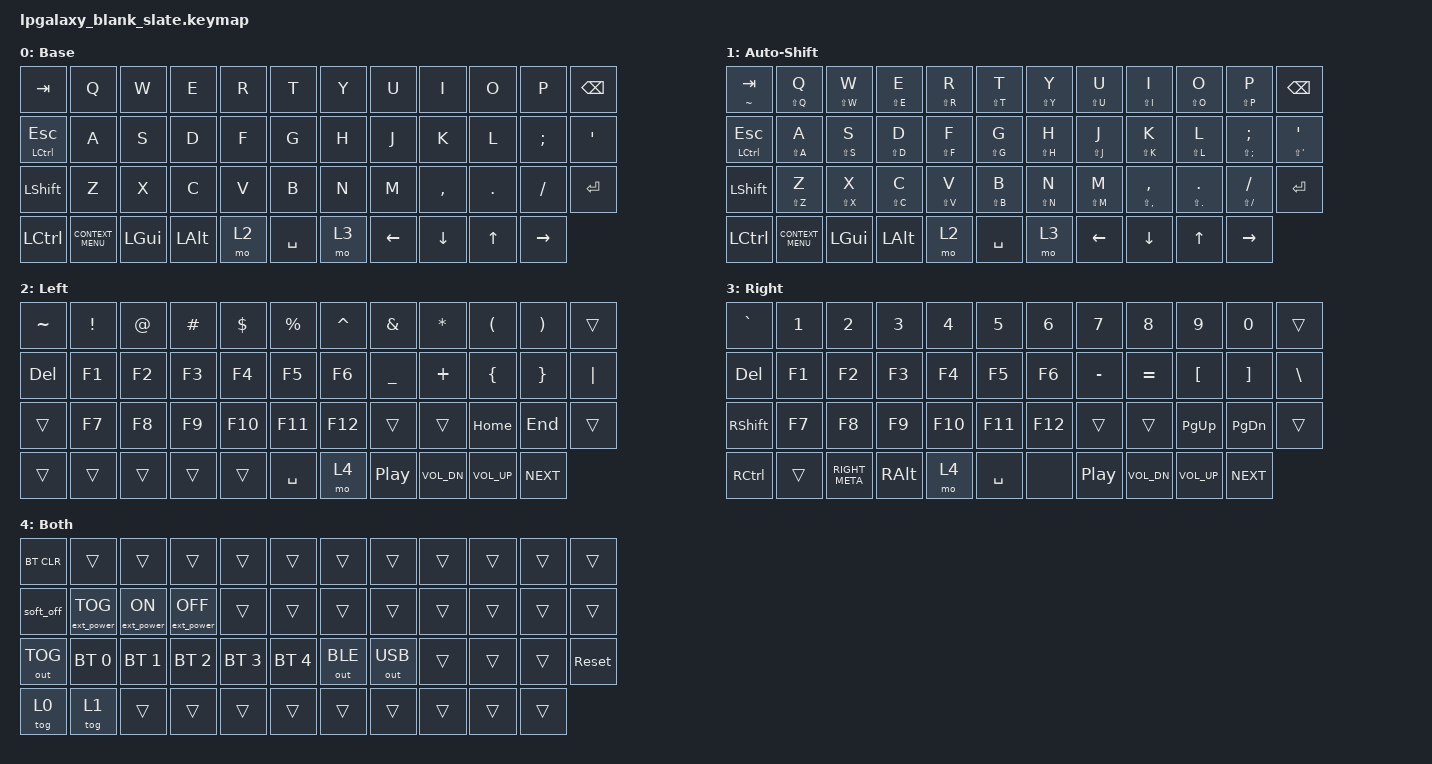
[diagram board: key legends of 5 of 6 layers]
/*
 * Copyright (c) 2022 Pete Johanson
 *
 * SPDX-License-Identifier: MIT
 */

#include <behaviors.dtsi>
#include <dt-bindings/zmk/bt.h>
#include <dt-bindings/zmk/ext_power.h>
#include <dt-bindings/zmk/keys.h>
#include <dt-bindings/zmk/outputs.h>

#define NAV_L 1
#define NUM_L 2
#define SYM_L 3

#define AS(keycode) &as LS(keycode) keycode

/ {
    chosen { zmk,physical-layout = &layout_ortho_4x12_1x2u; };

    behaviors {
        as: auto_shift {
            compatible = "zmk,behavior-hold-tap";
            #binding-cells = <2>;
            flavor = "tap-preferred";
            bindings = <&kp>, <&kp>;

            tapping-term-ms = <225>;
        };
    };

    keymap {
        compatible = "zmk,keymap";

        base_layer {
            label = "Base";
            bindings = <
&kp TAB                  &kp Q               &kp W     &kp E     &kp R  &kp T      &kp Y  &kp U     &kp I      &kp O         &kp P      &kp BACKSPACE
&as LEFT_CONTROL ESCAPE  &kp A               &kp S     &kp D     &kp F  &kp G      &kp H  &kp J     &kp K      &kp L         &kp SEMI   &kp SINGLE_QUOTE
&kp LSHFT                &kp Z               &kp X     &kp C     &kp V  &kp B      &kp N  &kp M     &kp COMMA  &kp DOT       &kp FSLH   &kp RET
&kp LCTRL                &kp K_CONTEXT_MENU  &kp LGUI  &kp LALT  &mo 2  &kp SPACE  &mo 3  &kp LEFT  &kp DOWN   &kp UP_ARROW  &kp RIGHT
            >;
        };

        AS_layer {
            label = "Auto-Shift";
            bindings = <
&as TILDE TAB         &as LS(Q) Q         &as LS(W) W  &as LS(E) E  &as LS(R) R  &as LS(T) T  &as LS(Y) Y  &as LS(U) U  &as LS(I) I          &as LS(O) O      &as LS(P) P                  &kp BACKSPACE
&as LEFT_CONTROL ESC  &as LS(A) A         &as LS(S) S  &as LS(D) D  &as LS(F) F  &as LS(G) G  &as LS(H) H  &as LS(J) J  &as LS(K) K          &as LS(L) L      &as LS(SEMICOLON) SEMICOLON  &as LS(SINGLE_QUOTE) SINGLE_QUOTE
&kp LSHFT             &as LS(Z) Z         &as LS(X) X  &as LS(C) C  &as LS(V) V  &as LS(B) B  &as LS(N) N  &as LS(M) M  &as LS(COMMA) COMMA  &as LS(DOT) DOT  &as LS(FSLH) FSLH            &kp RET
&kp LCTRL             &kp K_CONTEXT_MENU  &kp LGUI     &kp LALT     &mo 2        &kp SPACE    &mo 3        &kp LEFT     &kp DOWN             &kp UP_ARROW     &kp RIGHT
            >;
        };

        left_layer {
            label = "Left";
            bindings = <
&kp TILDE  &kp EXCLAMATION  &kp AT  &kp HASH  &kp DOLLAR  &kp PERCENT  &kp CARET  &kp AMPERSAND     &kp ASTERISK  &kp LPAR        &kp RPAR         &trans
&kp DEL    &kp F1           &kp F2  &kp F3    &kp F4      &kp F5       &kp F6     &kp UNDERSCORE    &kp PLUS      &kp LEFT_BRACE  &kp RIGHT_BRACE  &kp PIPE
&trans     &kp F7           &kp F8  &kp F9    &kp F10     &kp F11      &kp F12    &trans            &trans        &kp HOME        &kp END          &trans
&trans     &trans           &trans  &trans    &trans      &kp SPACE    &mo 4      &kp C_PLAY_PAUSE  &kp C_VOL_DN  &kp C_VOL_UP    &kp C_NEXT
            >;
        };

        right_layer {
            label = "Right";
            bindings = <
&kp GRAVE          &kp NUMBER_1  &kp NUMBER_2    &kp NUMBER_3   &kp NUMBER_4  &kp NUMBER_5  &kp NUMBER_6  &kp NUMBER_7      &kp NUMBER_8  &kp NUMBER_9      &kp N0             &trans
&kp DEL            &kp F1        &kp F2          &kp F3         &kp F4        &kp F5        &kp F6        &kp MINUS         &kp EQUAL     &kp LEFT_BRACKET  &kp RIGHT_BRACKET  &kp BACKSLASH
&kp RIGHT_SHIFT    &kp F7        &kp F8          &kp F9         &kp F10       &kp F11       &kp F12       &trans            &trans        &kp PAGE_UP       &kp PAGE_DOWN      &trans
&kp RIGHT_CONTROL  &trans        &kp RIGHT_META  &kp RIGHT_ALT  &mo 4         &kp SPACE     &none         &kp C_PLAY_PAUSE  &kp C_VOL_DN  &kp C_VOLUME_UP   &kp C_NEXT
            >;
        };

        both_layer {
            label = "Both";
            bindings = <
&bt BT_CLR    &trans             &trans            &trans             &trans        &trans        &trans        &trans        &trans  &trans  &trans  &trans
&soft_off     &ext_power EP_TOG  &ext_power EP_ON  &ext_power EP_OFF  &trans        &trans        &trans        &trans        &trans  &trans  &trans  &trans
&out OUT_TOG  &bt BT_SEL 0       &bt BT_SEL 1      &bt BT_SEL 2       &bt BT_SEL 3  &bt BT_SEL 4  &out OUT_BLE  &out OUT_USB  &trans  &trans  &trans  &sys_reset
&tog 0        &tog 1             &trans            &trans             &trans        &trans        &trans        &trans        &trans  &trans  &trans
            >;
        };

        layer_5 {
            bindings = <
&trans  &trans  &trans  &trans  &trans  &trans  &trans  &trans  &trans  &trans  &trans  &trans
&trans  &trans  &trans  &trans  &trans  &trans  &trans  &trans  &trans  &trans  &trans  &trans
&trans  &trans  &trans  &trans  &trans  &trans  &trans  &trans  &trans  &trans  &trans  &trans
&trans  &trans  &trans  &trans  &trans  &trans  &trans  &trans  &trans  &trans  &trans  &trans
            >;
        };
    };
};
